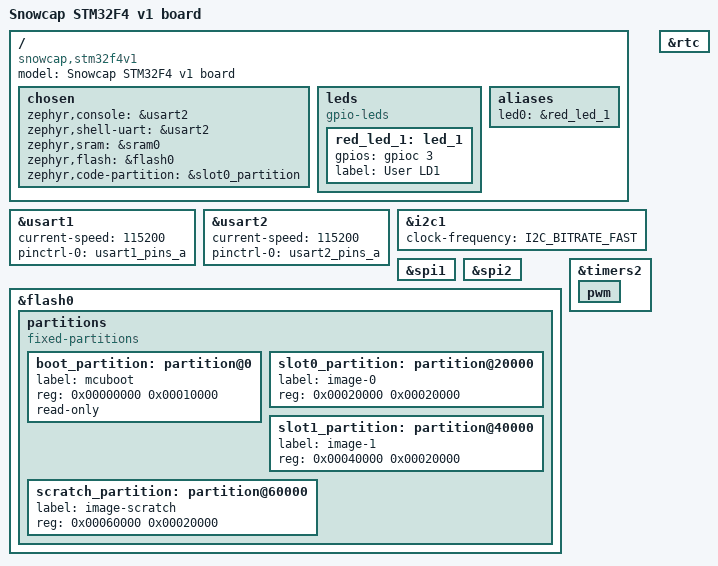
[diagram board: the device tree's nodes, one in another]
/*
 * Copyright (c) 2017 Linaro Limited
 * Copyright (c) 2019 Tuomas Kulve
 *
 * SPDX-License-Identifier: Apache-2.0
 */

/dts-v1/;
#include <st/f4/stm32f405Xg.dtsi>

/ {
	model = "Snowcap STM32F4 v1 board";
	compatible = "snowcap,stm32f4v1", "st,stm32f405";

	chosen {
		zephyr,console = &usart2;
		zephyr,shell-uart = &usart2;
		zephyr,sram = &sram0;
		zephyr,flash = &flash0;
		zephyr,code-partition = &slot0_partition;
	};

	leds {
		compatible = "gpio-leds";
		red_led_1: led_1 {
			gpios = <&gpioc 3 GPIO_INT_ACTIVE_HIGH>;
			label = "User LD1";
		};
	};

	aliases {
		led0 = &red_led_1;
	};
};

&usart1 {
	current-speed = <115200>;
	pinctrl-0 = <&usart1_pins_a>;
	pinctrl-names = "default";
	status = "ok";
};

&usart2 {
	current-speed = <115200>;
	pinctrl-0 = <&usart2_pins_a>;
	pinctrl-names = "default";
	status = "ok";
};

arduino_i2c: &i2c1 {
	status = "ok";
	clock-frequency = <I2C_BITRATE_FAST>;
};

arduino_spi: &spi1 {
	status = "ok";
};

&spi2 {
	status = "ok";
};

&flash0 {
	/*
	 * For more information, see:
	 * http://docs.zephyrproject.org/latest/guides/dts/index.html#flash-partitions
	 */
	partitions {
		compatible = "fixed-partitions";
		#address-cells = <1>;
		#size-cells = <1>;

		boot_partition: partition@0 {
			label = "mcuboot";
			reg = <0x00000000 0x00010000>;
			read-only;
		};

		/*
		 * The flash starting at offset 0x10000 and ending at
		 * offset 0x1ffff is reserved for use by the application.
		 */

		slot0_partition: partition@20000 {
			label = "image-0";
			reg = <0x00020000 0x00020000>;
		};
		slot1_partition: partition@40000 {
			label = "image-1";
			reg = <0x00040000 0x00020000>;
		};
		scratch_partition: partition@60000 {
			label = "image-scratch";
			reg = <0x00060000 0x00020000>;
		};
	};


};

&timers2 {
	status = "ok";

	pwm {
		status = "ok";
	};
};

&rtc {
	status = "ok";
};
